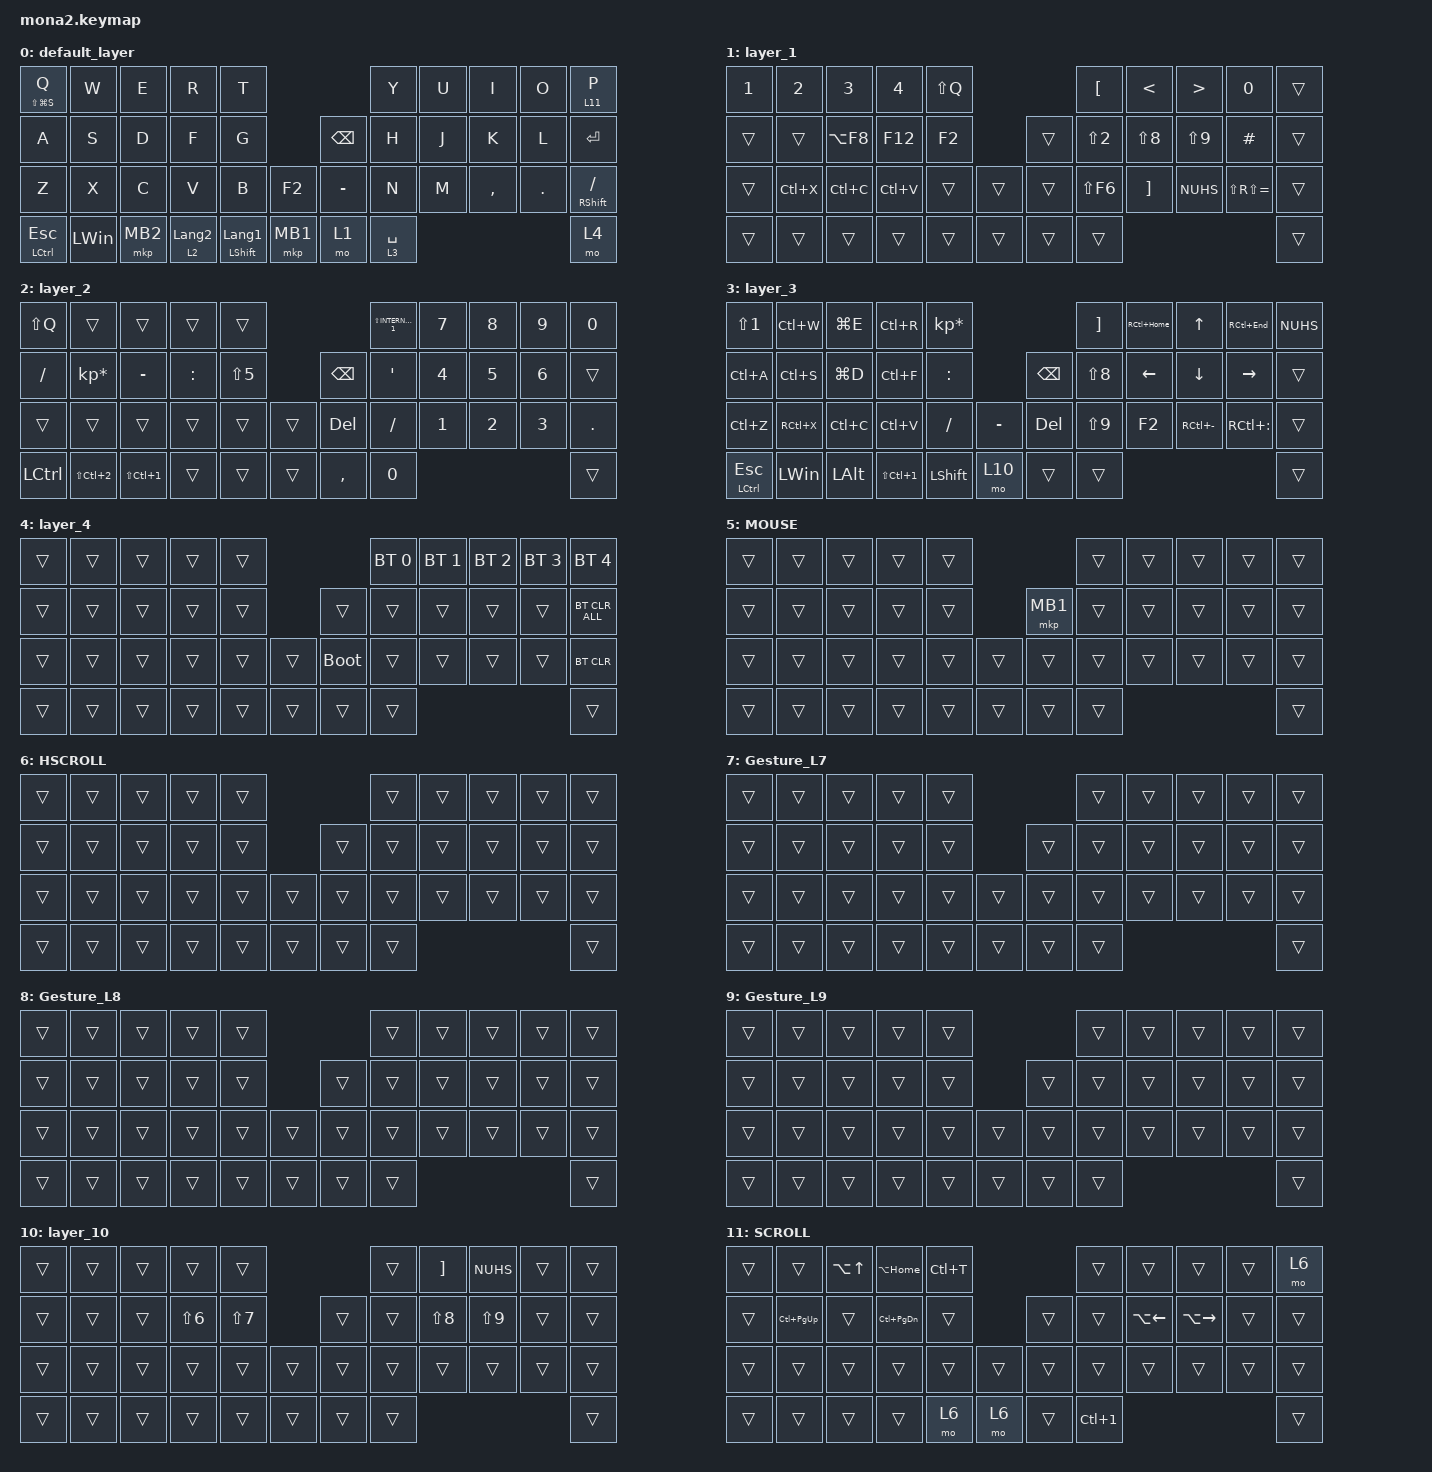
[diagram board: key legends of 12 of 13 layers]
#include <behaviors.dtsi>
#include <dt-bindings/zmk/bt.h>
#include <dt-bindings/zmk/keys.h>
#include <dt-bindings/zmk/pointing.h>

#define ZMK_POINTING_DEFAULT_SCRL_VAL 100
#define MOUSE 5

&mt {
    flavor = "balanced";
    quick-tap-ms = <0>;
};

&lt {
    quick-tap-ms = <200>;
    flavor = "balanced";
};

/ {
    // Layer 8 に入ったら英数(LANGUAGE_2)に切替、抜けても英数のまま
    // (Layer 2 の強制英数は無効化)

    eisuu_listeners {
        compatible = "zmk,layer-listeners";

        eisuu_on_l8 {
            layers = <8>;
            bindings = <&kp LANGUAGE_2 &none>;
        };
    };

    combos {
        compatible = "zmk,combos";

        Gesture_L8 {
            bindings = <&mo 12>;
            key-positions = <8 9>;
            require-prior-idle-ms = <150>;
        };

        a {
            bindings = <&none>;
            key-positions = <17 29 18 19 31 10 21>;
            require-prior-idle-ms = <150>;
        };

        Gesture_L11 {
            bindings = <&kp LG(TAB)>;
            key-positions = <9 40>;
            require-prior-idle-ms = <150>;
        };

        Tab {
            bindings = <&kp TAB>;
            key-positions = <18 19>;
            require-prior-idle-ms = <150>;
        };

        ESC_key {
            bindings = <&kp ESC>;
            key-positions = <0 1>;
            require-prior-idle-ms = <150>;
        };

        atai {
            bindings = <&kp LS(LC(V))>;
            key-positions = <23 24>;
        };

        // 左手親指(34:MB2 + 35:LALT)を押している間、横スクロールレイヤー(11)有効。
        // 右手でトラックボールを左右に回すとExcel横スクロール(縦スクロールしない)。

        hscroll {
            bindings = <&kp LG(TAB)>;
            key-positions = <9 39>;
        };

        kp_Q {
            bindings = <&kp LS(Q)>;
            key-positions = <13 14>;
        };

        KP_sum {
            bindings = <&kp LA(LS(MINUS))>;
            key-positions = <12 11>;
        };

        KP_EQUA {
            bindings = <&kp LS(MINUS)>;
            key-positions = <13 12>;
        };

        keisikiharituke {
            bindings = <&kp LC(LA(V))>;
            key-positions = <23 22>;
        };
    };

    macros {
        to_layer_0: to_layer_0 {
            compatible = "zmk,behavior-macro-one-param";
            #binding-cells = <1>;
            bindings = <&to 0 &macro_param_1to1 &kp MACRO_PLACEHOLDER>;
            label = "TO_LAYER_0";
        };

        mul_mark: x_sign_win {
            compatible = "zmk,behavior-macro";
            #binding-cells = <0>;
            wait-ms = <10>;
            tap-ms = <10>;
            bindings =
                <&macro_press>,
                <&kp LALT>,
                <&macro_tap>,
                <&kp KP_N0 &kp KP_N2 &kp KP_N1 &kp KP_N5>,
                <&macro_release>,
                <&kp LALT>;
        };

        div_mark: div_mark {
            compatible = "zmk,behavior-macro";
            label = "DIV_MARK";
            #binding-cells = <0>;
            wait-ms = <10>;
            tap-ms = <10>;
            bindings =
                <&macro_press>,
                <&kp LALT>,
                <&macro_tap>,
                <&kp KP_N0 &kp KP_N2 &kp KP_N4 &kp KP_N7>,
                <&macro_release>,
                <&kp LALT>;
        };

        exit_AML: exit_AML {
            compatible = "zmk,behavior-macro";
            wait-ms = <0>;
            tap-ms = <0>;
            #binding-cells = <0>;
            bindings = <&tog_off 5>;
            label = "exit_AML";
        };

        kp_exit_AML: kp_exit_AML {
            compatible = "zmk,behavior-macro-one-param";
            wait-ms = <0>;
            tap-ms = <0>;
            #binding-cells = <1>;
            bindings = <&macro_param_1to1 &kp MACRO_PLACEHOLDER &exit_AML>;
            label = "KP_exit_AML";
        };

        alt_tab_swap: alt_tab_swap {
            compatible = "zmk,behavior-macro";
            #binding-cells = <0>;
            wait-ms = <0>;
            tap-ms = <0>;
            bindings =
                <&macro_press>,
                <&kp LALT>,
                <&macro_tap>,
                <&kp TAB>,
                <&macro_press>,
                <&mo 10>,
                <&macro_pause_for_release>,
                <&macro_release>,
                <&mo 10>,
                <&macro_release>,
                <&kp LALT>;

            label = "ALT_TAB_SWAP";
        };

        // メール返信用プロンプト挿入マクロ（# あり版 / JIS配列・Windows）
        // 取りこぼす場合は wait-ms / tap-ms を 30 に上げる

        mail_reply: mail_reply {
            compatible = "zmk,behavior-macro";
            #binding-cells = <0>;
            wait-ms = <20>;
            tap-ms = <20>;
            label = "MAIL_REPLY";
            bindings =
                <&macro_tap>,
                <&kp LANG2>,
                <&macro_tap>,
                <&kp LS(N3) &kp I &kp N &kp S &kp T &kp R &kp U &kp C &kp T &kp I &kp O &kp N &kp LS(ENTER) &kp R &kp E &kp A &kp D &kp SPACE &kp T &kp H &kp E &kp SPACE &kp J &kp A &kp P &kp A &kp N &kp E &kp S &kp E &kp SPACE &kp E &kp M &kp A &kp I &kp L &kp SPACE &kp B &kp E &kp L &kp O &kp W &kp SPACE &kp A &kp N &kp D &kp SPACE &kp D &kp R &kp A &kp F &kp T &kp SPACE &kp A &kp SPACE &kp R &kp E &kp P &kp L &kp Y &kp DOT &kp LS(ENTER) &kp R &kp E &kp P &kp L &kp Y &kp SPACE &kp I &kp N &kp SPACE &kp P &kp O &kp L &kp I &kp T &kp E &kp SPACE &kp J &kp A &kp P &kp A &kp N &kp E &kp S &kp E &kp DOT &kp LS(ENTER) &kp LS(ENTER) &kp LS(N3) &kp P &kp O &kp L &kp I &kp C &kp Y &kp LS(ENTER) &kp LS(ENTER) &kp LS(N3) &kp E &kp M &kp A &kp I &kp L &kp LS(ENTER) &kp LC(V)>;
        };
    };

    behaviors {
        lt_to_layer_0: lt_to_layer_0 {
            compatible = "zmk,behavior-hold-tap";
            label = "LAYER_TAP_TO_0";
            #binding-cells = <2>;
            tapping-term-ms = <200>;
            bindings = <&mo>, <&to_layer_0>;
        };

        mo_tap: mo_on_tap {
            compatible = "zmk,behavior-hold-tap";
            label = "MO_ON_TAP";
            #binding-cells = <2>;
            tapping-term-ms = <200>;
            flavor = "balanced";
            bindings = <&mo>, <&mo>;
        };

        // アルファキー用レイヤータップ。タイプ中(直前150ms以内に打鍵)は
        // 即タップ判定し後続キーをキャプチャしないため、連続入力での遅延蓄積を防ぐ

        hl: home_layer_tap {
            compatible = "zmk,behavior-hold-tap";
            label = "HOME_LAYER_TAP";
            #binding-cells = <2>;
            flavor = "tap-preferred";
            tapping-term-ms = <200>;
            quick-tap-ms = <200>;
            require-prior-idle-ms = <150>;
            bindings = <&mo>, <&kp>;
        };

        scroll_up_down: mouse_wheel_up_down {
            compatible = "zmk,behavior-sensor-rotate";
            #sensor-binding-cells = <0>;
            tap-ms = <20>;
            bindings = <&msc SCRL_DOWN>, <&msc SCRL_UP>;
        };

        scroll_right_left: mouse_wheel_right_left {
            compatible = "zmk,behavior-sensor-rotate";
            #sensor-binding-cells = <0>;
            tap-ms = <20>;
            bindings = <&msc SCRL_LEFT>, <&msc SCRL_RIGHT>;
        };

        tog_off: toggle_layer_off {
            compatible = "zmk,behavior-toggle-layer";
            #binding-cells = <1>;
            display-name = "Toggle Layer Off";
            toggle-mode = "off";
        };

        mt_exit_AML_on_tap: mt_exit_AML_on_tap {
            compatible = "zmk,behavior-hold-tap";
            label = "MT_exit_AML_ON_TAP";
            bindings = <&kp>, <&kp_exit_AML>;

            #binding-cells = <2>;
            tapping-term-ms = <200>;
            flavor = "balanced";
            quick-tap-ms = <200>;
        };

        // 左手ホームロウmod：右手＋親指を押したときだけホールド成立

        hml: home_row_mod_left {
            compatible = "zmk,behavior-hold-tap";
            #binding-cells = <2>;
            flavor = "tap-preferred";
            tapping-term-ms = <200>;
            quick-tap-ms = <175>;
            require-prior-idle-ms = <220>;
            hold-trigger-on-release;
            hold-trigger-key-positions = <5 6 7 8 9 15 16 17 18 19 20 27 28 29 30 31 32 36 37 38 39 40 41>;
            bindings = <&kp>, <&kp>;
        };

        // 右手ホームロウmod：左手＋親指を押したときだけホールド成立

        hmr: home_row_mod_right {
            compatible = "zmk,behavior-hold-tap";
            #binding-cells = <2>;
            flavor = "tap-preferred";
            tapping-term-ms = <200>;
            quick-tap-ms = <175>;
            require-prior-idle-ms = <220>;
            hold-trigger-on-release;
            hold-trigger-key-positions = <0 1 2 3 4 10 11 12 13 14 15 21 22 23 24 25 26 27 36 37 38 39 40 41>;
            bindings = <&kp>, <&kp>;
        };
    };

    keymap {
        compatible = "zmk,keymap";

        default_layer {
            bindings = <
&mt LS(LG(S)) Q  &kp W         &kp E     &kp R             &kp T                                                 &kp Y        &kp U  &kp I      &kp O    &hl 11 P
&kp A            &kp S         &kp D     &kp F             &kp G                                  &kp BACKSPACE  &kp H        &kp J  &kp K      &kp L    &kp ENTER
&kp Z            &kp X         &kp C     &kp V             &kp B                      &kp F2      &kp MINUS      &kp N        &kp M  &kp COMMA  &kp DOT  &hmr RIGHT_SHIFT SLASH
&hml LCTRL ESC   &kp LEFT_WIN  &mkp MB2  &lt 2 LANGUAGE_2  &mt LEFT_SHIFT LANGUAGE_1  &mkp MB1    &mo 1          &lt 3 SPACE                             &mo 4
            >;

            sensor-bindings = <&scroll_up_down>;
        };

        layer_1 {
            bindings = <
&kp N1  &kp N2     &kp N3      &kp N4     &kp LS(Q)                    &kp LBKT    &kp LESS_THAN  &kp GREATER_THAN  &kp N0             &trans
&trans  &trans     &kp LA(F8)  &kp F12    &kp F2               &trans  &kp LS(N2)  &kp LS(N8)     &kp LS(N9)        &kp HASH           &trans
&trans  &kp LC(X)  &kp LC(C)   &kp LC(V)  &trans     &trans    &trans  &kp LS(F6)  &kp RBKT       &kp NUHS          &kp LS(RS(EQUAL))  &trans
&trans  &trans     &trans      &trans     &trans     &trans    &trans  &trans                                                          &trans
            >;

            sensor-bindings = <&inc_dec_kp LA(TAB) LS(LA(TAB))>;
        };

        layer_2 {
            bindings = <
&kp LS(Q)  &trans           &trans          &trans     &trans                               &kp LS(INTERNATIONAL_1)  &kp N7  &kp N8  &kp N9  &kp N0
&kp SLASH  &kp KP_MULTIPLY  &kp MINUS       &kp COLON  &kp LS(N5)            &kp BACKSPACE  &kp SQT                  &kp N4  &kp N5  &kp N6  &trans
&trans     &trans           &trans          &trans     &trans      &trans    &kp DEL        &kp SLASH                &kp N1  &kp N2  &kp N3  &kp DOT
&kp LCTRL  &kp LS(LC(N2))   &kp LS(LC(N1))  &trans     &trans      &trans    &kp COMMA      &kp N0                                           &trans
            >;

            sensor-bindings = <&scroll_up_down>;
        };

        layer_3 {
            bindings = <
&kp LS(N1)     &kp LC(W)     &kp LG(E)     &kp LC(R)       &kp KP_MULTIPLY                              &kp RBKT    &kp RC(HOME)    &kp UP_ARROW    &kp RC(END)      &kp NUHS
&kp LC(A)      &kp LC(S)     &kp LG(D)     &kp LC(F)       &kp COLON                     &kp BACKSPACE  &kp LS(N8)  &kp LEFT_ARROW  &kp DOWN_ARROW  &kp RIGHT_ARROW  &trans
&kp LC(Z)      &kp RC(X)     &kp LC(C)     &kp LC(V)       &kp SLASH        &kp MINUS    &kp DEL        &kp LS(N9)  &kp F2          &kp RC(MINUS)   &kp RC(COLON)    &trans
&mt LCTRL ESC  &kp LEFT_WIN  &kp LEFT_ALT  &kp LS(LC(N1))  &kp LEFT_SHIFT   &mo 10       &trans         &trans                                                       &trans
            >;

            sensor-bindings = <&scroll_up_down>;
        };

        layer_4 {
            bindings = <
&trans  &trans  &trans  &trans  &trans                         &bt BT_SEL 0  &bt BT_SEL 1  &bt BT_SEL 2  &bt BT_SEL 3  &bt BT_SEL 4
&trans  &trans  &trans  &trans  &trans            &trans       &trans        &trans        &trans        &trans        &bt BT_CLR_ALL
&trans  &trans  &trans  &trans  &trans  &trans    &bootloader  &trans        &trans        &trans        &trans        &bt BT_CLR
&trans  &trans  &trans  &trans  &trans  &trans    &trans       &trans                                                  &trans
            >;

            sensor-bindings = <&scroll_up_down>;
        };

        MOUSE {
            bindings = <
&trans  &trans  &trans  &trans  &trans                      &trans  &trans  &trans  &trans  &trans
&trans  &trans  &trans  &trans  &trans            &mkp MB1  &trans  &trans  &trans  &trans  &trans
&trans  &trans  &trans  &trans  &trans  &trans    &trans    &trans  &trans  &trans  &trans  &trans
&trans  &trans  &trans  &trans  &trans  &trans    &trans    &trans                          &trans
            >;

            sensor-bindings = <&scroll_up_down>;
        };

        HSCROLL {
            bindings = <
&trans  &trans  &trans  &trans  &trans                    &trans  &trans  &trans  &trans  &trans
&trans  &trans  &trans  &trans  &trans            &trans  &trans  &trans  &trans  &trans  &trans
&trans  &trans  &trans  &trans  &trans  &trans    &trans  &trans  &trans  &trans  &trans  &trans
&trans  &trans  &trans  &trans  &trans  &trans    &trans  &trans                          &trans
            >;
        };

        Gesture_L7 {
            bindings = <
&trans  &trans  &trans  &trans  &trans                    &trans  &trans  &trans  &trans  &trans
&trans  &trans  &trans  &trans  &trans            &trans  &trans  &trans  &trans  &trans  &trans
&trans  &trans  &trans  &trans  &trans  &trans    &trans  &trans  &trans  &trans  &trans  &trans
&trans  &trans  &trans  &trans  &trans  &trans    &trans  &trans                          &trans
            >;
        };

        Gesture_L8 {
            bindings = <
&trans  &trans  &trans  &trans  &trans                    &trans  &trans  &trans  &trans  &trans
&trans  &trans  &trans  &trans  &trans            &trans  &trans  &trans  &trans  &trans  &trans
&trans  &trans  &trans  &trans  &trans  &trans    &trans  &trans  &trans  &trans  &trans  &trans
&trans  &trans  &trans  &trans  &trans  &trans    &trans  &trans                          &trans
            >;
        };

        Gesture_L9 {
            bindings = <
&trans  &trans  &trans  &trans  &trans                    &trans  &trans  &trans  &trans  &trans
&trans  &trans  &trans  &trans  &trans            &trans  &trans  &trans  &trans  &trans  &trans
&trans  &trans  &trans  &trans  &trans  &trans    &trans  &trans  &trans  &trans  &trans  &trans
&trans  &trans  &trans  &trans  &trans  &trans    &trans  &trans                          &trans
            >;
        };

        layer_10 {
            bindings = <
&trans  &trans  &trans  &trans      &trans                        &trans  &kp RBKT    &kp NUHS    &trans  &trans
&trans  &trans  &trans  &kp LS(N6)  &kp LS(N7)            &trans  &trans  &kp LS(N8)  &kp LS(N9)  &trans  &trans
&trans  &trans  &trans  &trans      &trans      &trans    &trans  &trans  &trans      &trans      &trans  &trans
&trans  &trans  &trans  &trans      &trans      &trans    &trans  &trans                                  &trans
            >;
        };

        SCROLL {
            bindings = <
&trans  &trans           &kp LA(UP)  &kp LA(HOME)       &kp LC(T)                    &trans            &trans        &trans         &trans  &mo 6
&trans  &kp LC(PAGE_UP)  &trans      &kp LC(PAGE_DOWN)  &trans               &trans  &trans            &kp LA(LEFT)  &kp LA(RIGHT)  &trans  &trans
&trans  &trans           &trans      &trans             &trans     &trans    &trans  &trans            &trans        &trans         &trans  &trans
&trans  &trans           &trans      &trans             &mo 6      &mo 6     &trans  &kp LC(NUMBER_1)                                       &trans
            >;

            sensor-bindings = <&scroll_right_left>;
        };

        layer_12 {
            bindings = <
&trans         &trans            &kp LA(SPACE)  &trans             &trans                       &trans  &trans  &trans  &trans  &trans
&kp LESS_THAN  &kp LG(LC(LEFT))  &kp LS(LG(D))  &kp LG(LC(RIGHT))  &trans               &trans  &trans  &trans  &trans  &trans  &trans
&trans         &trans            &trans         &trans             &trans     &trans    &trans  &trans  &trans  &trans  &trans  &trans
&trans         &trans            &trans         &trans             &kp GRAVE  &trans    &trans  &trans                          &trans
            >;
        };
    };
};
